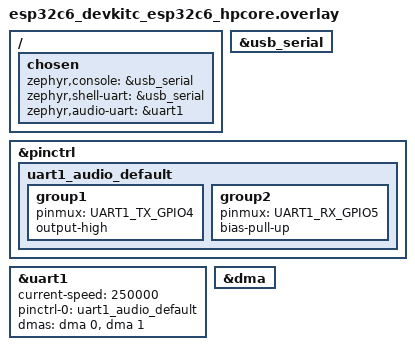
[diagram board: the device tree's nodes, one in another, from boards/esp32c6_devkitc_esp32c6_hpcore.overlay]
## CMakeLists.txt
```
# SPDX-License-Identifier: Apache-2.0

cmake_minimum_required(VERSION 3.20.0)

find_package(Zephyr REQUIRED HINTS $ENV{ZEPHYR_BASE})
project(esp32c6_audio_modem)

target_include_directories(app PRIVATE src)

target_sources(app PRIVATE
  src/main.c
  src/features/uart_audio/uart_audio.c
)

target_sources_ifdef(CONFIG_AUDIO_MODEM_SOURCE_SINE app PRIVATE
  src/features/audio_source/sine_source.c
)

target_sources_ifdef(CONFIG_AUDIO_MODEM_SOURCE_UDP app PRIVATE
  src/features/jitter_buffer/jitter_buffer.c
  src/features/udp_audio/udp_audio.c
  src/features/wifi_station/wifi_station.c
)
```

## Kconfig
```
# Copyright (c) 2026 Yuancheng Li
# SPDX-License-Identifier: Apache-2.0

mainmenu "ESP32-C6 audio modem"

source "Kconfig.zephyr"

menu "Audio modem"

choice AUDIO_MODEM_SOURCE
	prompt "Audio source"
	default AUDIO_MODEM_SOURCE_UDP

config AUDIO_MODEM_SOURCE_UDP
	bool "Wi-Fi UDP audio"

config AUDIO_MODEM_SOURCE_SINE
	bool "Local sine-wave test source"

endchoice

config AUDIO_MODEM_WIFI_SSID
	string "Wi-Fi SSID"
	default ""
	depends on AUDIO_MODEM_SOURCE_UDP
	help
	  Station SSID. Keep site-specific values in an untracked wifi.conf file.

config AUDIO_MODEM_WIFI_PSK
	string "Wi-Fi pre-shared key"
	default ""
	depends on AUDIO_MODEM_SOURCE_UDP
	help
	  WPA/WPA2 pre-shared key. An empty value selects an open network.

config AUDIO_MODEM_UDP_PORT
	int "UDP audio listen port"
	default 4242
	range 1 65535
	depends on AUDIO_MODEM_SOURCE_UDP

config AUDIO_MODEM_JITTER_BUFFER_PACKETS
	int "Jitter buffer capacity in packets"
	default 8
	range 3 16
	depends on AUDIO_MODEM_SOURCE_UDP

config AUDIO_MODEM_JITTER_BUFFER_START_PACKETS
	int "Packets required before playback starts"
	default 3
	range 1 16
	depends on AUDIO_MODEM_SOURCE_UDP

endmenu
```

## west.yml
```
# Copyright (c) 2026 Yuancheng Li
# SPDX-License-Identifier: Apache-2.0

manifest:
  remotes:
    - name: zephyrproject-rtos
      url-base: https://github.com/zephyrproject-rtos
  
  projects:
    - name: zephyr
      remote: zephyrproject-rtos
      revision: main
      import: true

  self:
    path: app
```

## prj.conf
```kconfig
#
# Copyright (c) 2026 Yuancheng Li
# SPDX-License-Identifier: Apache-2.0
#

CONFIG_SERIAL=y
CONFIG_UART_INTERRUPT_DRIVEN=n
CONFIG_UART_ASYNC_API=n
CONFIG_DMA=y

CONFIG_HEAP_MEM_POOL_SIZE=120832

CONFIG_NETWORKING=y
CONFIG_NET_IPV4=y
CONFIG_NET_IPV6=n
CONFIG_NET_UDP=y
CONFIG_NET_SOCKETS=y
CONFIG_NET_DHCPV4=y

CONFIG_WIFI=y
CONFIG_WIFI_NM=y
CONFIG_WIFI_USAGE_MODE_STA=y
CONFIG_ESP32_WIFI_STA_RECONNECT=y

CONFIG_CONSOLE=y
CONFIG_UART_CONSOLE=y
CONFIG_PRINTK=y
CONFIG_LOG=y
CONFIG_DEBUG=y
CONFIG_DEBUG_THREAD_INFO=y

CONFIG_MAIN_STACK_SIZE=4096
CONFIG_ESPTOOLPY_FLASHSIZE_8MB=y

CONFIG_SYSTEM_WORKQUEUE_STACK_SIZE=4096
CONFIG_STACK_SENTINEL=y

CONFIG_NET_RX_STACK_SIZE=4096
CONFIG_LOG_PROCESS_THREAD_STACK_SIZE=2048
```

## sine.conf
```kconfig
# Copyright (c) 2026 Yuancheng Li
# SPDX-License-Identifier: Apache-2.0

CONFIG_AUDIO_MODEM_SOURCE_SINE=y
```

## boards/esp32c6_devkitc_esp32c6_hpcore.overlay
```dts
/*
 * Copyright (c) 2026 Yuancheng Li
 * SPDX-License-Identifier: Apache-2.0
 *
 * ESP32-C6 UART audio output for MSPM0 UART1 RX.
 *
 * Recommended wiring:
 *   ESP32-C6 GPIO4 / UART1 TX -> MSPM0 PA9 / UART1 RX
 *   ESP32-C6 GPIO5 / UART1 RX <- MSPM0 PA17 / UART1 TX, optional for later control
 *   ESP32-C6 GND              -> MSPM0 GND
 */

#include <zephyr/dt-bindings/pinctrl/esp32c6-pinctrl.h>

/ {
	chosen {
		zephyr,console = &usb_serial;
		zephyr,shell-uart = &usb_serial;
		zephyr,audio-uart = &uart1;
	};
};

&usb_serial {
	status = "okay";
};

&pinctrl {
	uart1_audio_default: uart1_audio_default {
		group1 {
			pinmux = <UART1_TX_GPIO4>;
			output-high;
		};

		group2 {
			pinmux = <UART1_RX_GPIO5>;
			bias-pull-up;
		};
	};
};

&uart1 {
	status = "okay";
	current-speed = <250000>;
	pinctrl-0 = <&uart1_audio_default>;
	pinctrl-names = "default";
	dmas = <&dma 0>, <&dma 1>;
	dma-names = "rx", "tx";
};

&dma {
	status = "okay";
};
```

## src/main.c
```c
/*
 * Copyright (c) 2026 Yuancheng Li
 * SPDX-License-Identifier: Apache-2.0
 */

#include <stdint.h>

#include <zephyr/device.h>
#include <zephyr/devicetree.h>
#include <zephyr/kernel.h>
#include <zephyr/sys/printk.h>

#include "features/uart_audio/uart_audio.h"

#if defined(CONFIG_AUDIO_MODEM_SOURCE_SINE)
#include "features/audio_source/audio_source.h"
#else
#include "features/jitter_buffer/jitter_buffer.h"
#include "features/udp_audio/udp_audio.h"
#include "features/wifi_station/wifi_station.h"
#endif

#define AUDIO_UART_NODE DT_CHOSEN(zephyr_audio_uart)

#if !DT_NODE_HAS_STATUS(AUDIO_UART_NODE, okay)
#error "No enabled zephyr,audio-uart chosen node. Check the board devicetree overlay."
#endif

#define SAMPLE_RATE_HZ 5000U
#define FRAME_SAMPLES 128U

#if defined(CONFIG_AUDIO_MODEM_SOURCE_UDP)
static struct jitter_buffer jitter_buffer;
#endif

int main(void)
{
	const struct device *audio_uart = DEVICE_DT_GET(AUDIO_UART_NODE);
	struct uart_audio_stream stream;
#if defined(CONFIG_AUDIO_MODEM_SOURCE_SINE)
	struct audio_source source;
#endif
	uint16_t samples[FRAME_SAMPLES];
	uint64_t stream_start_us;
	int64_t next_status_ms;
	uint64_t sample_cursor = 0U;
	int ret;

	if (!device_is_ready(audio_uart))
	{
		printk("Audio UART device is not ready\n");
		return 0;
	}

	ret = uart_audio_stream_init(&stream, audio_uart);
	if (ret != 0)
	{
		printk("Audio UART initialization failed: %d\n", ret);
		return 0;
	}

#if defined(CONFIG_AUDIO_MODEM_SOURCE_SINE)
	sine_source_init(&source, SAMPLE_RATE_HZ);
#else
	jitter_buffer_init(&jitter_buffer);
	ret = wifi_station_init();
	if (ret != 0)
	{
		printk("Wi-Fi station initialization failed: %d\n", ret);
		return 0;
	}

	ret = udp_audio_start(&jitter_buffer);
	if (ret != 0)
	{
		printk("UDP audio initialization failed: %d\n", ret);
		return 0;
	}

	ret = wifi_station_connect();
	if (ret != 0)
	{
		printk("Wi-Fi connection request failed: %d\n", ret);
	}
#endif

	printk("ESP32-C6 UART audio streamer: %u Hz, %u samples/frame, %u baud\n",
		   SAMPLE_RATE_HZ, FRAME_SAMPLES,
		   DT_PROP(AUDIO_UART_NODE, current_speed));

	stream_start_us = k_ticks_to_us_floor64(k_uptime_ticks());
	next_status_ms = k_uptime_get() + 1000;

	while (true)
	{
#if defined(CONFIG_AUDIO_MODEM_SOURCE_SINE)
		source.fill(&source, samples, FRAME_SAMPLES);
#else
		jitter_buffer_pop(&jitter_buffer, samples, FRAME_SAMPLES);
#endif
		ret = uart_audio_send_frame(&stream, samples, FRAME_SAMPLES);
		if (ret != 0)
		{
			printk("Audio UART transmission failed: %d\n", ret);
		}
		/*
		if (k_uptime_get() >= next_status_ms)
		{
			printk("Audio UART TX completed: %u frames\n",
				   uart_audio_completed_frames(&stream));
			next_status_ms += 1000;
		}
		*/

		sample_cursor += FRAME_SAMPLES;

		uint64_t target_us = stream_start_us +
							 ((sample_cursor * 1000000ULL) / SAMPLE_RATE_HZ);
		int64_t sleep_us = (int64_t)target_us -
						   (int64_t)k_ticks_to_us_floor64(k_uptime_ticks());

		if (sleep_us > 0)
		{
			k_sleep(K_USEC(sleep_us));
		}
	}

	return 0;
}
```
